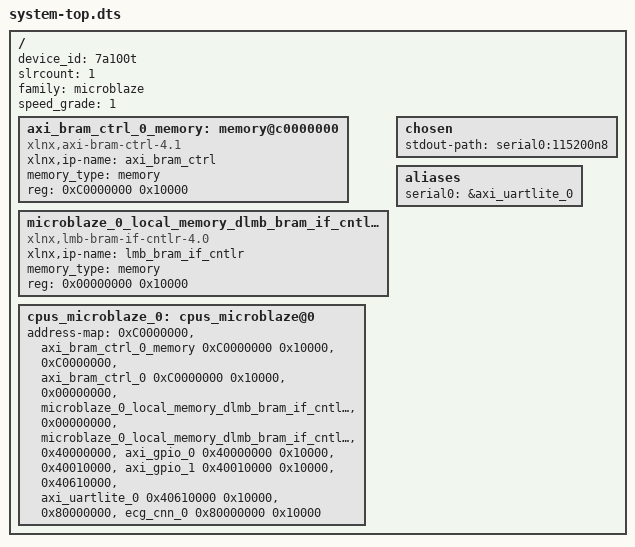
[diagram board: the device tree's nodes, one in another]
/dts-v1/;
#include "pl.dtsi"
/ {
	device_id = "7a100t";
	#address-cells = <1>;
	#size-cells = <1>;
	slrcount = <1>;
	family = "microblaze";
	speed_grade = "1";
	axi_bram_ctrl_0_memory: memory@c0000000 {
		compatible = "xlnx,axi-bram-ctrl-4.1";
		xlnx,ip-name = "axi_bram_ctrl";
		device_type = "memory";
		memory_type = "memory";
		reg = <0xC0000000 0x10000>;
	};
	microblaze_0_local_memory_dlmb_bram_if_cntlr_memory: memory@0 {
		compatible = "xlnx,lmb-bram-if-cntlr-4.0";
		xlnx,ip-name = "lmb_bram_if_cntlr";
		device_type = "memory";
		memory_type = "memory";
		reg = <0x00000000 0x10000>;
	};
	chosen {
		stdout-path = "serial0:115200n8";
	};
	aliases {
		serial0 = &axi_uartlite_0;
	};
	cpus_microblaze_0: cpus_microblaze@0 {
		address-map = <0xC0000000 &axi_bram_ctrl_0_memory 0xC0000000 0x10000>, 
			      <0xC0000000 &axi_bram_ctrl_0 0xC0000000 0x10000>, 
			      <0x00000000 &microblaze_0_local_memory_dlmb_bram_if_cntlr_memory 0x00000000 0x10000>, 
			      <0x00000000 &microblaze_0_local_memory_dlmb_bram_if_cntlr 0x00000000 0x10000>, 
			      <0x40000000 &axi_gpio_0 0x40000000 0x10000>, 
			      <0x40010000 &axi_gpio_1 0x40010000 0x10000>, 
			      <0x40610000 &axi_uartlite_0 0x40610000 0x10000>, 
			      <0x80000000 &ecg_cnn_0 0x80000000 0x10000>;
		#ranges-address-cells = <0x1>;
		#ranges-size-cells = <0x1>;
	};
};
